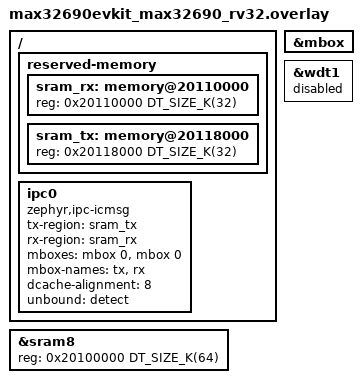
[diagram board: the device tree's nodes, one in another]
/*
 * Copyright (c) 2025 Analog Devices, Inc
 *
 * SPDX-License-Identifier: Apache-2.0
 */

// Use less of SRAM8 for the RV32 core, so we have memory available to share with the ARM core
&sram8 {
	reg = <0x20100000 DT_SIZE_K(64)>;
};

&mbox {
	status = "okay";
};

// Don't use the WDT to reboot, since that reboots both cores
&wdt1 {
	status = "disabled";
};

/ {
	reserved-memory {
		#address-cells = <1>;
		#size-cells = <1>;
		ranges;

		sram_rx: memory@20110000 {
			reg = <0x20110000 DT_SIZE_K(32)>;
		};

		sram_tx: memory@20118000 {
			reg = <0x20118000 DT_SIZE_K(32)>;
		};
	};

	ipc0: ipc0 {
		compatible = "zephyr,ipc-icmsg";
		tx-region = <&sram_tx>;
		rx-region = <&sram_rx>;
		mboxes = <&mbox 0>, <&mbox 0>;
		mbox-names = "tx", "rx";
		dcache-alignment = <8>;
		unbound = "detect";
		status = "okay";
	};
};
